AUTOSAR XML (schema 4-2-2)
package /AUTOSAR_Dcm/SwComponentTypes
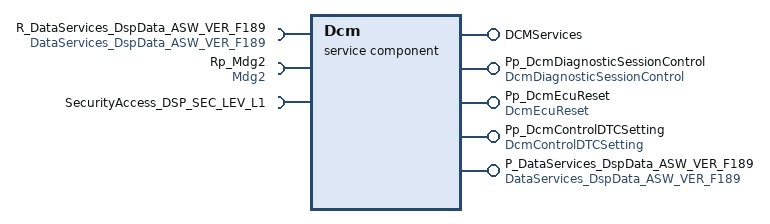
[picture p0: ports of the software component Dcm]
  service sw component type Dcm
    4 x provide port:
      DCMServices: provided-interface=DCMServices
        provided-com-specs:
          operation=GetActiveProtocol, queue-length=1
          operation=SetActiveDiagnostic, queue-length=1
          operation=GetSesCtrlType, queue-length=1
          operation=GetSecurityLevel, queue-length=1
          operation=ResetToDefaultSession, queue-length=1
      Pp_DcmDiagnosticSessionControl: mode-switch-sender-com-spec{mode-group=MDGP_DcmDiagnosticSessionControl, queue-length=1}, provided-interface=DcmDiagnosticSessionControl
      Pp_DcmEcuReset: mode-switch-sender-com-spec{mode-group=MDGP_DcmEcuReset, queue-length=1}, provided-interface=DcmEcuReset
      Pp_DcmControlDTCSetting: mode-switch-sender-com-spec{mode-group=MDGP_DcmControlDTCSetting, queue-length=1}, provided-interface=DcmControlDTCSetting
    require port R_DataServices_DspData_ASW_VER_F189: required-interface=DataServices_DspData_ASW_VER_F189
    provide port P_DataServices_DspData_ASW_VER_F189: provided-interface=DataServices_DspData_ASW_VER_F189
    require port Rp_Mdg2: mode-switch-receiver-com-spec=supports-asynchronous-mode-switch=true, required-interface=Mdg2
    require port SecurityAccess_DSP_SEC_LEV_L1: required-interface=SecurityAccess_DSP_SEC_LEV_L1
    behavior IntBeh_Dcm: data-type-mapping=[DTS_DcmDiagnosticSessionControl, DTS_DcmEcuReset, DTS_DcmControlDTCSetting, DTS_Mdg2], included-data-type-set=data-type=[Dcm_SecLevelType, Dcm_SesCtrlType, Dcm_ProtocolType, Dcm_NegativeResponseCodeType, Dcm_ConfirmationStatusType, Dcm_OpStatusType, Dcm_DidSupportedType], port-api-option{enable-take-address=true, indirect-api=false, port=SecurityAccess_DSP_SEC_LEV_L1}
      5 x operation invoked event:
        OpInvEvent_DCMServices_GAP: start-on-event=Dcm_GetActiveProtocol, operation=DCMServices.GetActiveProtocol
        OpInvEvent_DCMServices_SAD: start-on-event=Dcm_SetActiveDiagnostic, operation=DCMServices.SetActiveDiagnostic
        OpInvEvent_DCMServices_GSCT: start-on-event=Dcm_GetSesCtrlType, operation=DCMServices.GetSesCtrlType
        OpInvEvent_DCMServices_GSL: start-on-event=Dcm_GetSecurityLevel, operation=DCMServices.GetSecurityLevel
        OpInvEvent_DCMServices_RD: start-on-event=Dcm_ResetToDefaultSession, operation=DCMServices.ResetToDefaultSession
      6 x runnable:
        Dcm_MainFunction: mode-access-point=Rp_Mdg2.MDGP_Mdg2
          data-receive-point-by-arguments:
            access DspData_ASW_VER_F189_Read: accessed-variable=R_DataServices_DspData_ASW_VER_F189.Data
          data-send-points:
            access DspData_ASW_VER_F189_Write: accessed-variable=P_DataServices_DspData_ASW_VER_F189.Data
          mode switch point ModeSwitchPoint_0: mode-group=Pp_DcmDiagnosticSessionControl.MDGP_DcmDiagnosticSessionControl
          mode switch point ModeSwitchPoint_1: mode-group=Pp_DcmEcuReset.MDGP_DcmEcuReset
          mode switch point ModeSwitchPoint_3: mode-group=Pp_DcmControlDTCSetting.MDGP_DcmControlDTCSetting
          sync call SSC_SeCa_DSP_SEC_LEV_L1_GS: operation=SecurityAccess_DSP_SEC_LEV_L1.GetSeed, timeout=0.0
          sync call SSC_SeCa_DSP_SEC_LEV_L1_CK: operation=SecurityAccess_DSP_SEC_LEV_L1.CompareKey, timeout=0.0
        Dcm_GetActiveProtocol: can-be-invoked-concurrently=true
        Dcm_SetActiveDiagnostic: can-be-invoked-concurrently=true
        Dcm_GetSesCtrlType: can-be-invoked-concurrently=true
        Dcm_GetSecurityLevel: can-be-invoked-concurrently=true
        Dcm_ResetToDefaultSession: can-be-invoked-concurrently=true
package /AUTOSAR_Dcm/SwcImplementations
  swc implementation Impl_Dcm: programming-language=C, sw-version=42.9.0.0, swc-bsw-mapping=SwcBswMappings, vendor-id=6, behavior=IntBeh_Dcm
    code-descriptors:
      code CodeDescr_Dcm: artifact-descriptors=autosar-engineering-object={short-label=Code_0, category=SWSRC}
package /AUTOSAR_Dcm/CompuMethods
  compu method Dcm_RidSupportedType_Values: 0=DCM_RID_SUPPORTED_IN_RANGE, 1=DCM_RID_NOT_SUPPORTED
package /AUTOSAR_Dcm/ImplementationDataTypes
  10 x impl type:
    Dcm_SesCtrlType: compu {1=DCM_DEFAULT_SESSION, 2=DCM_PROGRAMMING_SESSION, 3=DCM_EXTENDED_DIAGNOSTIC_SESSION, 4=DCM_SAFETY_SYSTEM_DIAGNOSTIC_SESSION, 65=CODING_SESSION}, implementation-data-type=uint8
    Dcm_NegativeResponseCodeType: compu {0=DCM_POS_RESP, 17=DCM_E_SERVICENOTSUPPORTED, 18=DCM_E_SUBFUNCTIONNOTSUPPORTED, 19=DCM_E_INCORRECTMESSAGELENGTHORINVALIDFORMAT, 20=DCM_E_RESPONSETOOLONG, 53=DCM_E_INVALIDKEY, 54=DCM_E_EXCEEDNUMBEROFATTEMPTS, 55=DCM_E_REQUIREDTIMEDELAYNOTEXPIRED, 112=DCM_E_UPLOADDOWNLOADNOTACCEPTED, 113=DCM_E_TRANSFERDATASUSPENDED, 115=DCM_E_WRONGBLOCKSEQUENCECOUNTER, 127=DCM_E_SERVICENOTSUPPORTEDINACTIVESESSION, 140=DCM_E_TRANSMISSIONRANGENOTINNEUTRAL, 34=DCM_E_CONDITIONSNOTCORRECT, 16=DCM_E_GENERALREJECT, 33=DCM_E_BUSYREPEATREQUEST, 36=DCM_E_REQUESTSEQUENCEERROR, 37=DCM_E_NORESPONSEFROMSUBNETCOMPONENT, 38=DCM_E_FAILUREPREVENTSEXECUTIONOFREQUESTEDACTION, 49=DCM_E_REQUESTOUTOFRANGE, 51=DCM_E_SECURITYACCESSDENIED, 114=DCM_E_GENERALPROGRAMMINGFAILURE, 126=DCM_E_SUBFUNCTIONNOTSUPPORTEDINACTIVESESSION, 129=DCM_E_RPMTOOHIGH, 130=DCM_E_RPMTOOLOW, 131=DCM_E_ENGINEISRUNNING, 132=DCM_E_ENGINEISNOTRUNNING, 133=DCM_E_ENGINERUNTIMETOOLOW, 134=DCM_E_TEMPERATURETOOHIGH, 135=DCM_E_TEMPERATURETOOLOW, 136=DCM_E_VEHICLESPEEDTOOHIGH, 137=DCM_E_VEHICLESPEEDTOOLOW, 138=DCM_E_THROTTLE_PEDALTOOHIGH, 139=DCM_E_THROTTLE_PEDALTOOLOW, 141=DCM_E_TRANSMISSIONRANGENOTINGEAR, 146=DCM_E_VOLTAGETOOHIGH, 143=DCM_E_BRAKESWITCH_NOTCLOSED, 144=DCM_E_SHIFTERLEVERNOTINPARK, 145=DCM_E_TORQUECONVERTERCLUTCHLOCKED, 147=DCM_E_VOLTAGETOOLOW, 0=DCM_E_POSITIVERESPONSE, 120=DCM_E_REQUESTCORRECTLYRECEIVEDRESPONSEPENDING, 148=DCM_E_RESOURCETEMPORARILYNOTAVAILABLE, 240..249=DCM_E_VMSCNC_0..DCM_E_VMSCNC_9, 250=DCM_E_VMSCNC_A, 251=DCM_E_VMSCNC_B, 252=DCM_E_VMSCNC_C, 253=DCM_E_VMSCNC_D, 254=DCM_E_VMSCNC_E}, implementation-data-type=uint8
    Dcm_DataArrayTypeUint8_DspData_ASW_VER_F189Type: category=ARRAY
      element DataArray: array-size=8, array-size-semantics=FIXED-SIZE, implementation-data-type=uint8
    Dcm_ConfirmationStatusType: compu {0=DCM_RES_POS_OK, 1=DCM_RES_POS_NOT_OK, 2=DCM_RES_NEG_OK, 3=DCM_RES_NEG_NOT_OK}, implementation-data-type=uint8
    Dcm_ProtocolType: compu {0=DCM_OBD_ON_CAN, 1=DCM_OBD_ON_FLEXRAY, 2=DCM_OBD_ON_IP, 3=DCM_UDS_ON_CAN, 4=DCM_UDS_ON_FLEXRAY, 5=DCM_UDS_ON_IP, 6=DCM_ROE_ON_CAN, 7=DCM_ROE_ON_FLEXRAY, 8=DCM_ROE_ON_IP, 9=DCM_PERIODICTRANS_ON_CAN, 10=DCM_PERIODICTRANS_ON_FLEXRAY, 11=DCM_PERIODICTRANS_ON_IP, 12=DCM_NO_ACTIVE_PROTOCOL, 144=DCM_ACEA_ON_CAN, 145=DCM_ACEA_ON_FLEXRAY, 128=DCM_KWP_ON_KLINE, 129=DCM_KWP_ON_CAN, 160=DCM_CARB_ON_KLINE, 161=DCM_OBD_ON_KLINE, 240..254=DCM_SUPPLIER_1..DCM_SUPPLIER_15}, implementation-data-type=uint8
    Dcm_SecLevelType: compu {1=DCM_SEC_LEV_L1}, implementation-data-type=uint8
    Dcm_SeedArray_DSP_SEC_LEV_L1Type: category=ARRAY
      element DcmDspSecuritySeedSize_DSP_SEC_LEV_L1: array-size=2, array-size-semantics=FIXED-SIZE, implementation-data-type=uint8
    Dcm_KeyArray_DSP_SEC_LEV_L1Type: category=ARRAY
      element DcmDspSecurityKeySize_1: array-size=2, array-size-semantics=FIXED-SIZE, implementation-data-type=uint8
    Dcm_OpStatusType: compu {0=DCM_INITIAL, 1=DCM_PENDING, 2=DCM_CANCEL, 3=DCM_FORCE_RCRRP_OK}, implementation-data-type=uint8
    Dcm_DidSupportedType: compu {0=DCM_DID_SUPPORTED, 1=DCM_DID_NOT_SUPPORTED}, implementation-data-type=uint8
package /AUTOSAR_Dcm/DataTypeMappingSets
  4 x data type mapping set:
    DTS_DcmDiagnosticSessionControl: mode-request-type-map{implementation-data-type=uint8, mode-group=DcmDiagnosticSessionControl}
    DTS_DcmEcuReset: mode-request-type-map{implementation-data-type=uint8, mode-group=DcmEcuReset}
    DTS_DcmControlDTCSetting: mode-request-type-map{implementation-data-type=uint8, mode-group=DcmControlDTCSetting}
    DTS_Mdg2: mode-request-type-map{implementation-data-type=uint8, mode-group=Mdg2}
package /AUTOSAR_Dcm/SwcBswMappings
  swc bsw mapping SwcBswMappings: bsw-behavior=BswInternalBehavior, swc-bsw-runnable-mapping{bsw-entity=BSWSE_DcmMainFunction, swc-runnable=Dcm_MainFunction}, swc-behavior=IntBeh_Dcm
    synchronized-mode-groups:
      bsw-mode-group=DcmDiagnosticSessionControl, swc-mode-group=Pp_DcmDiagnosticSessionControl.MDGP_DcmDiagnosticSessionControl
      bsw-mode-group=DcmEcuReset, swc-mode-group=Pp_DcmEcuReset.MDGP_DcmEcuReset
      bsw-mode-group=DcmControlDTCSetting, swc-mode-group=Pp_DcmControlDTCSetting.MDGP_DcmControlDTCSetting
package /AUTOSAR_Dcm/PortInterfaces
  sender receiver interface DataServices_DspData_ASW_VER_F189
    data Data: type=Dcm_DataArrayTypeUint8_DspData_ASW_VER_F189Type
  client server interface DCMServices: is-service=true
    5 x operation:
      GetActiveProtocol: possible-error=[DCMServices/E_OK, DCMServices/E_NOT_OK]
        arg ActiveProtocol: type=Dcm_ProtocolType, direction=OUT
      SetActiveDiagnostic: possible-error=DCMServices/E_OK
        arg active: type=boolean, direction=IN
      GetSesCtrlType: possible-error=[DCMServices/E_OK, DCMServices/E_NOT_OK]
        arg SesCtrlType: type=Dcm_SesCtrlType, direction=OUT
      GetSecurityLevel: possible-error=[DCMServices/E_OK, DCMServices/E_NOT_OK]
        arg SecLevel: type=Dcm_SecLevelType, direction=OUT
      ResetToDefaultSession: possible-error=[DCMServices/E_OK, DCMServices/E_NOT_OK]
    error E_OK: error-code=0
    error E_NOT_OK: error-code=1
  client server interface SecurityAccess_DSP_SEC_LEV_L1: is-service=true
    operation GetSeed: possible-error=[SecurityAccess_DSP_SEC_LEV_L1/E_OK, SecurityAccess_DSP_SEC_LEV_L1/E_NOT_OK, DCM_E_PENDING]
      arg OpStatus: type=Dcm_OpStatusType, direction=IN
      arg Seed: type=Dcm_SeedArray_DSP_SEC_LEV_L1Type, direction=OUT
      arg ErrorCode: type=Dcm_NegativeResponseCodeType, direction=OUT
    operation CompareKey: possible-error=[SecurityAccess_DSP_SEC_LEV_L1/E_OK, SecurityAccess_DSP_SEC_LEV_L1/E_NOT_OK, DCM_E_PENDING, DCM_E_COMPARE_KEY_FAILED]
      arg Key: type=Dcm_KeyArray_DSP_SEC_LEV_L1Type, direction=IN
      arg OpStatus: type=Dcm_OpStatusType, direction=IN
      arg ErrorCode: type=Dcm_NegativeResponseCodeType, direction=OUT
    4 x error:
      E_OK: error-code=0
      E_NOT_OK: error-code=1
      DCM_E_PENDING: error-code=10
      DCM_E_COMPARE_KEY_FAILED: error-code=11
  4 x mode switch interface, all with is-service=true:
    DcmDiagnosticSessionControl
      mode group MDGP_DcmDiagnosticSessionControl: type=DcmDiagnosticSessionControl
    DcmEcuReset
      mode group MDGP_DcmEcuReset: type=DcmEcuReset
    DcmControlDTCSetting
      mode group MDGP_DcmControlDTCSetting: type=DcmControlDTCSetting
    Mdg2
      mode group MDGP_Mdg2: type=Mdg2
